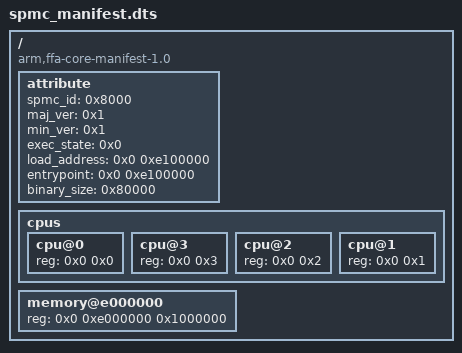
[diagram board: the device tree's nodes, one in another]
/*
 * Copyright 2022 The Hafnium Authors.
 *
 * Use of this source code is governed by a BSD-style
 * license that can be found in the LICENSE file or at
 * https://opensource.org/licenses/BSD-3-Clause.
 */

/*
 * FF-A SPMC manifest describing OP-TEE (running as the SPMC at S-EL1) to
 * TF-A's SPMD, for TF-A's "qemu" platform (QEMU virt machine). This is
 * TF-A's TOS_FW_CONFIG image, passed via QEMU_TOS_FW_CONFIG_DTS.
 *
 * Values (load address, secure memory region, CPU count) match the
 * BL32 layout produced by optee-os for PLATFORM=vexpress-qemu_armv8a and
 * the qemu_aarch64_virt_defconfig -smp setting.
 *
 * Taken as-is from the OP-TEE build repository
 * (qemu_v8/spmc_el1_manifest_virt.dts), which targets the same TF-A
 * "qemu" plat/OP-TEE PLATFORM combination used here.
 * https://github.com/OP-TEE/build
 */

/dts-v1/;

/ {
	compatible = "arm,ffa-core-manifest-1.0";
	#address-cells = <2>;
	#size-cells = <1>;

	attribute {
		spmc_id = <0x8000>;
		maj_ver = <0x1>;
		min_ver = <0x1>;
		exec_state = <0x0>;
		load_address = <0x0 0xe100000>;
		entrypoint = <0x0 0xe100000>;
		binary_size = <0x80000>;
	};

	cpus {
		#address-cells = <0x02>;
		#size-cells = <0x00>;

		cpu@0 {
			device_type = "cpu";
			reg = <0x0 0x0>;
		};

		cpu@3 {
			device_type = "cpu";
			reg = <0x0 0x3>;
		};

		cpu@2 {
			device_type = "cpu";
			reg = <0x0 0x2>;
		};

		cpu@1 {
			device_type = "cpu";
			reg = <0x0 0x1>;
		};
	};

	/* VIRT_SECURE_MEM */
	memory@e000000 {
		device_type = "memory";
		reg = <0x0 0xe000000 0x1000000>;
	};
};
